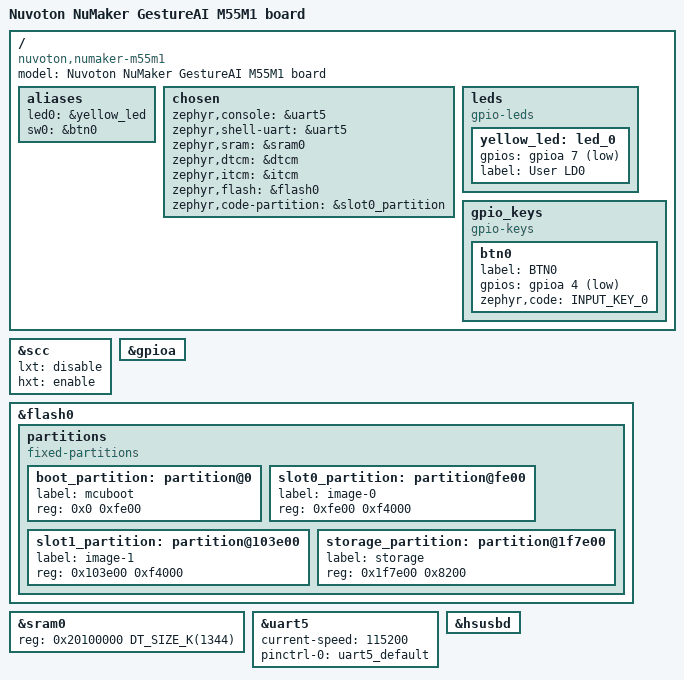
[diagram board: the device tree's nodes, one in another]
/*
 * Copyright (c) 2026 Nuvoton Technology Corporation.
 *
 * SPDX-License-Identifier: Apache-2.0
 */

/dts-v1/;

#include <nuvoton/m55m1h2l.dtsi>
#include "numaker_gai_m55m1-pinctrl.dtsi"
#include <zephyr/dt-bindings/input/input-event-codes.h>

/ {
	model = "Nuvoton NuMaker GestureAI M55M1 board";
	compatible = "nuvoton,numaker-m55m1";

	aliases {
		led0 = &yellow_led;
		sw0 = &btn0;
	};

	chosen {
		zephyr,console = &uart5;
		zephyr,shell-uart = &uart5;
		zephyr,sram = &sram0;
		zephyr,dtcm = &dtcm;
		zephyr,itcm = &itcm;
		zephyr,flash = &flash0;
		zephyr,code-partition = &slot0_partition;
	};

	leds {
		compatible = "gpio-leds";

		yellow_led: led_0 {
			gpios = <&gpioa 7 GPIO_ACTIVE_LOW>;
			label = "User LD0";
		};
	};

	gpio_keys {
		compatible = "gpio-keys";

		btn0: btn0 {
			label = "BTN0";
			gpios = <&gpioa 4 GPIO_ACTIVE_LOW>;
			zephyr,code = <INPUT_KEY_0>;
		};
	};
};

&scc {
	lxt = "disable";
	hxt = "enable";
};

&gpioa {
	status = "okay";
};

&flash0 {
	partitions {
		compatible = "fixed-partitions";
		#address-cells = <1>;
		#size-cells = <1>;

		boot_partition: partition@0 {
			label = "mcuboot";
			reg = <0x0 0xfe00>;
		};

		slot0_partition: partition@fe00 {
			label = "image-0";
			reg = <0xfe00 0xf4000>;
		};

		slot1_partition: partition@103e00 {
			label = "image-1";
			reg = <0x103e00 0xf4000>;
		};

		storage_partition: partition@1f7e00 {
			label = "storage";
			reg = <0x1f7e00 0x8200>;
		};
	};
};

&sram0 {
	reg = <0x20100000 DT_SIZE_K(1344)>;
};

&uart5 {
	current-speed = <115200>;
	pinctrl-0 = <&uart5_default>;
	pinctrl-names = "default";
	status = "okay";
};

/* On enabled, husbd phy is required HXT. */
zephyr_udc0: &hsusbd {
	/* Needn't pinctrl for pins being dedicated */
	status = "okay";
};
